# wsoc_ocp_ic_secure register map
Vendor: Texas Instruments
Peripheral module from a debugger description file (folder CC35X1).
Registers are 32-bit, access per field, no defined reset value unless marked. A register's access mark holds for its fields unless they carry their own. Offsets are as the file gives them; lines under a group give offsets from that group; [hi:lo] are bit positions; {n}, {i} and the like mark numbered series; 'fields as' and 'values as' point back to an identical list; <NAME> marks a mode.

## wsoc_ocp_ic_secure
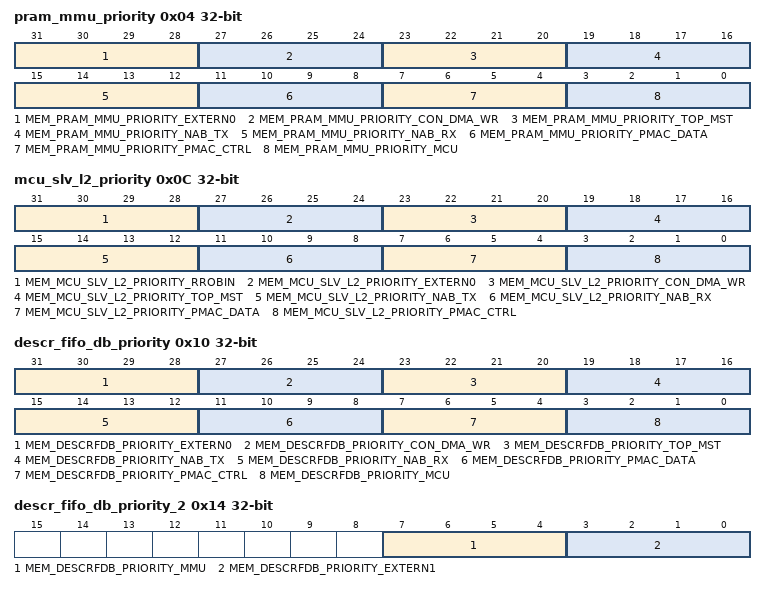
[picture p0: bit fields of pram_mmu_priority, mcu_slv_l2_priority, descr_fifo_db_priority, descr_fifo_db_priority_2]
0x04 pram_mmu_priority rw
  [31:28] MEM_PRAM_MMU_PRIORITY_EXTERN0, [27:24] MEM_PRAM_MMU_PRIORITY_CON_DMA_WR, [23:20] MEM_PRAM_MMU_PRIORITY_TOP_MST, [19:16] MEM_PRAM_MMU_PRIORITY_NAB_TX, [15:12] MEM_PRAM_MMU_PRIORITY_NAB_RX, [11:8] MEM_PRAM_MMU_PRIORITY_PMAC_DATA, [7:4] MEM_PRAM_MMU_PRIORITY_PMAC_CTRL, [3:0] MEM_PRAM_MMU_PRIORITY_MCU
0x08 pram_mmu_priority_2
  [3:0] MEM_PRAM_MMU_PRIORITY_RROBIN rw
0x0C mcu_slv_l2_priority rw
  [31:28] MEM_MCU_SLV_L2_PRIORITY_RROBIN, [27:24] MEM_MCU_SLV_L2_PRIORITY_EXTERN0, [23:20] MEM_MCU_SLV_L2_PRIORITY_CON_DMA_WR, [19:16] MEM_MCU_SLV_L2_PRIORITY_TOP_MST, [15:12] MEM_MCU_SLV_L2_PRIORITY_NAB_TX, [11:8] MEM_MCU_SLV_L2_PRIORITY_NAB_RX, [7:4] MEM_MCU_SLV_L2_PRIORITY_PMAC_DATA, [3:0] MEM_MCU_SLV_L2_PRIORITY_PMAC_CTRL
0x10 descr_fifo_db_priority rw
  [31:28] MEM_DESCRFDB_PRIORITY_EXTERN0, [27:24] MEM_DESCRFDB_PRIORITY_CON_DMA_WR, [23:20] MEM_DESCRFDB_PRIORITY_TOP_MST, [19:16] MEM_DESCRFDB_PRIORITY_NAB_TX, [15:12] MEM_DESCRFDB_PRIORITY_NAB_RX, [11:8] MEM_DESCRFDB_PRIORITY_PMAC_DATA, [7:4] MEM_DESCRFDB_PRIORITY_PMAC_CTRL, [3:0] MEM_DESCRFDB_PRIORITY_MCU
0x14 descr_fifo_db_priority_2
  [7:4] MEM_DESCRFDB_PRIORITY_MMU rw, [3:0] MEM_DESCRFDB_PRIORITY_EXTERN1 rw
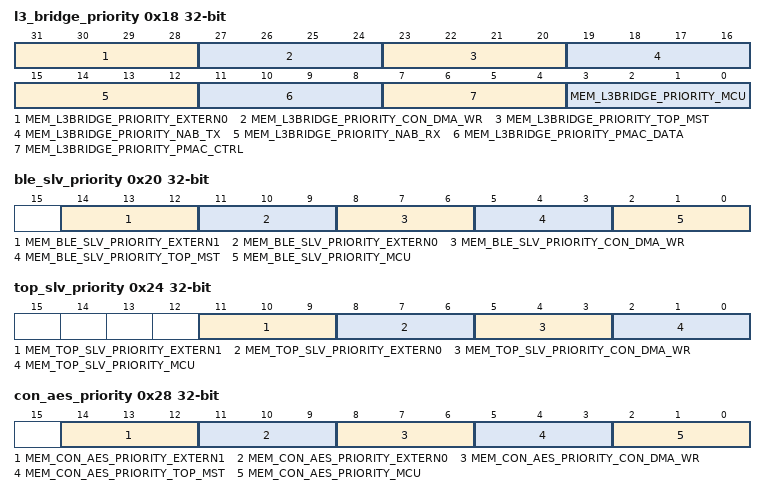
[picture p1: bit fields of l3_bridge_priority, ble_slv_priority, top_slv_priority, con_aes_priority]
0x18 l3_bridge_priority rw
  [31:28] MEM_L3BRIDGE_PRIORITY_EXTERN0, [27:24] MEM_L3BRIDGE_PRIORITY_CON_DMA_WR, [23:20] MEM_L3BRIDGE_PRIORITY_TOP_MST, [19:16] MEM_L3BRIDGE_PRIORITY_NAB_TX, [15:12] MEM_L3BRIDGE_PRIORITY_NAB_RX, [11:8] MEM_L3BRIDGE_PRIORITY_PMAC_DATA, [7:4] MEM_L3BRIDGE_PRIORITY_PMAC_CTRL, [3:0] MEM_L3BRIDGE_PRIORITY_MCU
0x1C l3_bridge_priority_2
  [3:0] MEM_L3BRIDGE_PRIORITY_RROBIN rw
0x20 ble_slv_priority
  [14:12] MEM_BLE_SLV_PRIORITY_EXTERN1 rw, [11:9] MEM_BLE_SLV_PRIORITY_EXTERN0 rw, [8:6] MEM_BLE_SLV_PRIORITY_CON_DMA_WR rw, [5:3] MEM_BLE_SLV_PRIORITY_TOP_MST rw, [2:0] MEM_BLE_SLV_PRIORITY_MCU rw
0x24 top_slv_priority
  [11:9] MEM_TOP_SLV_PRIORITY_EXTERN1 rw, [8:6] MEM_TOP_SLV_PRIORITY_EXTERN0 rw, [5:3] MEM_TOP_SLV_PRIORITY_CON_DMA_WR rw, [2:0] MEM_TOP_SLV_PRIORITY_MCU rw
0x28 con_aes_priority
  [14:12] MEM_CON_AES_PRIORITY_EXTERN1 rw, [11:9] MEM_CON_AES_PRIORITY_EXTERN0 rw, [8:6] MEM_CON_AES_PRIORITY_CON_DMA_WR rw, [5:3] MEM_CON_AES_PRIORITY_TOP_MST rw, [2:0] MEM_CON_AES_PRIORITY_MCU rw
0x38 timeout_cfg_slaves
  [8:4] MEM_SLV_TIMEOUT_VAL rw — value for timeout for all slaves: valid value - 0x0- 0x1F if value is 0 timeout feature is disabled for all slaves Granulation is double word (64b): 1 - means 16 clocks period, 2 - means 32 clocks period... in h/w the value in FIELD is shifted left 4 times (x16). example: 0x08 => 0x80 (8 means 128)
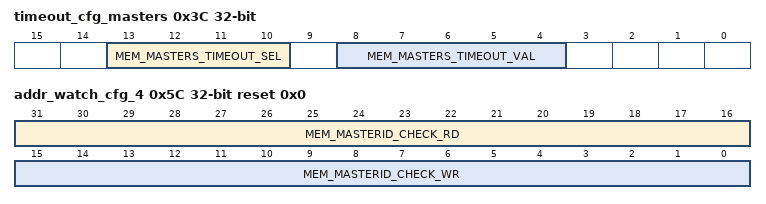
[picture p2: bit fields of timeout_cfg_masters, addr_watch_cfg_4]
0x3C timeout_cfg_masters
  [13:10] MEM_MASTERS_TIMEOUT_SEL rw — select master for timeout by masterid 0 - mcu 1 - pmac_ctrl 2 - pmac_data 3 - nab_rx 4 - nab_tx 5 - top_mst 6 - con_dma_wr 7 - con_dma_rd 8 - ble 9 - rs232 10 - phy 11 - mmu 12 - app
  [8:4] MEM_MASTERS_TIMEOUT_VAL rw — value for timeout for all slaves: valid value - 0x0- 0x1F if value is 0 timeout feature is disabled for all slaves Granulation is double word (64b): 1 - means 16 clocks period, 2 - means 32 clocks period... in h/w the value in FIELD is shifted left 4 times (x16). example: 0x08 => 0x80 (8 means 128)
0x48 ocp_slave_serror_and_timeout_1_status rw
  [31:0] MEM_SERROR_AND_TIMEOUT_STATUS_1_WROPT — status bits when ocp slave response with serror clear on write sticky - catch the first error, until register is cleared to 0 [31:0] - maddr *note - can only clear on write to 32'b0 writing 1 byte will clear all 4 bytes
0x4C ocp_slave_serror_and_timeout_2_status
  [9:0] MEM_SERROR_AND_TIMEOUT_STATUS_2_WROPT rw — status bits when ocp slave response with serror or timeout: clear on write sticky - catch the first error, until register is cleared to 0 for serror and timeout handeling: [9:6] cause [5:4] mcmd - command type: 2=RD ; 1=WR [3:0] masterid cause mapping: 0 - master 1 - pram_mmu 2 - mcu_slv_l2 3 - descrf_db 4 - L3bridge 5 - top_slv/wsoc2hif 6 - con_aes 7 - ble_slv masterid mapping: 0 - mcu 1 - pmac_ctrl 2 - pmac_data 3 - nab_rx 4 - nab_tx 5 - top_mst 6 - con_dma_wr 7 - con_dma_rd 8 - ble 9 - rs232 10 - phy 11 - mmu 12 - app *note - can only clear on write to 10'b0 writing 1 byte will clear all 2 bytes
0x50 addr_watch_cfg_1 reset 0x0
  [3:0] MEM_OCP_ADDR_WATCH_SLV_SEL rw — select which slave port of ocp_ic is checked in address-watch: 0 = PRAM/MMU 1 =MCU_SLV_L2 2 = Descriptor-FIFO / DB_RAM 3 = L3-Bridge 4 = CON_AES 5 = BLE_SLV 6 = TOP_SLV / WSOC2HIF
0x54 addr_watch_cfg_2 rw reset 0x0
  [31:0] MEM_OCP_ADDR_WATCH_LOW — lower maddr threshold for address-watch addr_hit = (maddr >= thr_low) & (maddr <= thr_high)
0x58 addr_watch_cfg_3 rw reset 0x0
  [31:0] MEM_OCP_ADDR_WATCH_HIGH — upper maddr threshold for address-watch addr_hit = (maddr >= thr_low) & (maddr <= thr_high)
0x5C addr_watch_cfg_4 rw reset 0x0
  [31:16] MEM_MASTERID_CHECK_RD — each bit enables check on MCMD=RD per MASTERID for example value of 0x0120 will enable check of masterid=5 and masterid=8 if check_wr=0x0000 and check_rd=0x0000 then the clock for address-watch is disabled locally to save power
  [15:0] MEM_MASTERID_CHECK_WR — each bit enables check on MCMD=WR per MASTERID for example value of 0x0120 will enable check of masterid=5 and masterid=8 if check_wr=0x0000 and check_rd=0x0000 then the clock for address-watch is disabled locally to save power
0x60 addr_watch_status_1 rw
  [31:0] OCP_IC_ADDR_WATCH_STATUS_1_WROPT — keep when hit - Clear on Write [31:0] - maddr
0x64 addr_watch_status_2
  [4:0] OCP_IC_ADDR_WATCH_STATUS_2_WROPT rw — keep when hit - Clear on Write [4] - command type: 0=RD ; 1=WR [3:0] - masterid masterid mapping: 0 - mcu 1 - pmac_ctrl 2 - pmac_data 3 - nab_rx 4 - nab_tx 5 - top_mst 6 - con_dma_wr 7 - con_dma_rd 8 - ble 9 - rs232 10 - phy 11 - mmu 12 - app
